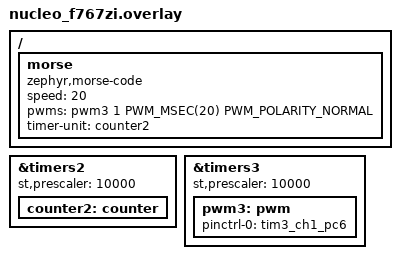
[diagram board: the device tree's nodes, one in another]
/*
 * Copyright (c) 2024 Freedom Veiculos Eletricos
 * Copyright (c) 2024 OS Systems
 *
 * SPDX-License-Identifier: Apache-2.0
 */

/ {
	morse: morse {
		compatible = "zephyr,morse-code";

		speed = <20>;
		pwms = <&pwm3 1 PWM_MSEC(20) PWM_POLARITY_NORMAL>;
		timer-unit = <&counter2>;
	};
};

&timers2 {
	st,prescaler = <10000>;
	status = "okay";

	counter2: counter {
		status = "okay";
	};
};

&timers3 {
	st,prescaler = <10000>;
	status = "okay";
	pwm3: pwm {
		status = "okay";
		pinctrl-0 = <&tim3_ch1_pc6>;
		pinctrl-names = "default";
	};
};

